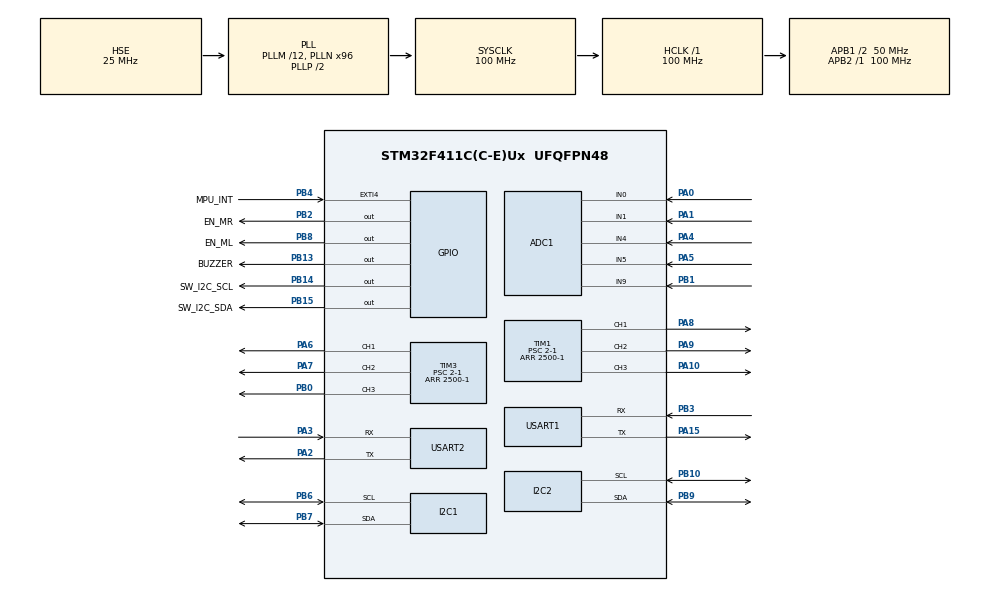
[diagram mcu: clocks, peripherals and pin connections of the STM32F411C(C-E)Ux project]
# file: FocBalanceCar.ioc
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ADC1.Channel-8\#ChannelRegularConversion=ADC_CHANNEL_1
ADC1.NbrOfConversionFlag=1
ADC1.Rank-8\#ChannelRegularConversion=1
ADC1.SamplingTime-8\#ChannelRegularConversion=ADC_SAMPLETIME_3CYCLES
ADC1.master=1
Dma.Request0=USART1_TX
Dma.Request1=USART2_TX
Dma.USART1_TX.0.Direction=DMA_MEMORY_TO_PERIPH
Dma.USART1_TX.0.FIFOMode=DMA_FIFOMODE_DISABLE
Dma.USART1_TX.0.Instance=DMA2_Stream7
Dma.USART1_TX.0.MemDataAlignment=DMA_MDATAALIGN_BYTE
Dma.USART1_TX.0.MemInc=DMA_MINC_ENABLE
Dma.USART1_TX.0.Mode=DMA_NORMAL
Dma.USART1_TX.0.PeriphDataAlignment=DMA_PDATAALIGN_BYTE
Dma.USART1_TX.0.PeriphInc=DMA_PINC_DISABLE
Dma.USART1_TX.0.Priority=DMA_PRIORITY_HIGH
Dma.USART2_TX.1.Direction=DMA_MEMORY_TO_PERIPH
Dma.USART2_TX.1.FIFOMode=DMA_FIFOMODE_DISABLE
Dma.USART2_TX.1.Instance=DMA1_Stream6
Dma.USART2_TX.1.MemDataAlignment=DMA_MDATAALIGN_BYTE
Dma.USART2_TX.1.MemInc=DMA_MINC_ENABLE
Dma.USART2_TX.1.Mode=DMA_NORMAL
Dma.USART2_TX.1.PeriphDataAlignment=DMA_PDATAALIGN_BYTE
Dma.USART2_TX.1.PeriphInc=DMA_PINC_DISABLE
Dma.USART2_TX.1.Priority=DMA_PRIORITY_HIGH
I2C1.I2C_Mode=I2C_Fast
I2C2.I2C_Mode=I2C_Fast
Mcu.Family=STM32F4
Mcu.Name=STM32F411C(C-E)Ux
Mcu.Package=UFQFPN48
NVIC.DMA1_Stream6_IRQn=true\:0\:0\:false\:false\:true\:false\:true\:true
NVIC.DMA2_Stream7_IRQn=true\:0\:0\:false\:false\:true\:false\:true\:true
NVIC.PriorityGroup=NVIC_PRIORITYGROUP_4
NVIC.TIM1_TRG_COM_TIM11_IRQn=true\:1\:0\:true\:false\:true\:true\:true\:true
NVIC.TIM1_UP_TIM10_IRQn=true\:1\:0\:true\:false\:true\:true\:true\:true
NVIC.USART1_IRQn=true\:0\:0\:true\:false\:true\:true\:true\:true
NVIC.USART2_IRQn=true\:0\:0\:true\:false\:true\:true\:true\:true
PA0-WKUP.Signal=ADCx_IN0
PA1.Signal=ADCx_IN1
PA10.GPIO_Speed=GPIO_SPEED_FREQ_HIGH
PA10.Signal=S_TIM1_CH3
PA13.Mode=Serial_Wire
PA13.Signal=SYS_JTMS-SWDIO
PA14.Mode=Serial_Wire
PA14.Signal=SYS_JTCK-SWCLK
PA15.Mode=Asynchronous
PA15.Signal=USART1_TX
PA2.Mode=Asynchronous
PA2.Signal=USART2_TX
PA3.Mode=Asynchronous
PA3.Signal=USART2_RX
PA4.Signal=ADCx_IN4
PA5.Signal=ADCx_IN5
PA6.GPIO_Speed=GPIO_SPEED_FREQ_HIGH
PA6.Signal=S_TIM3_CH1
PA7.GPIO_Speed=GPIO_SPEED_FREQ_HIGH
PA7.Signal=S_TIM3_CH2
PA8.GPIO_Speed=GPIO_SPEED_FREQ_HIGH
PA8.Signal=S_TIM1_CH1
PA9.GPIO_Speed=GPIO_SPEED_FREQ_HIGH
PA9.Signal=S_TIM1_CH2
PB0.Signal=S_TIM3_CH3
PB1.Signal=ADCx_IN9
PB10.Mode=I2C
PB10.Signal=I2C2_SCL
PB13.GPIO_Label=BUZZER
PB13.GPIO_Speed=GPIO_SPEED_FREQ_HIGH
PB13.Signal=GPIO_Output
PB14.GPIO_Label=SW_I2C_SCL
PB14.GPIO_ModeDefaultOutputPP=GPIO_MODE_OUTPUT_OD
PB14.GPIO_PuPd=GPIO_NOPULL
PB14.GPIO_Speed=GPIO_SPEED_FREQ_HIGH
PB14.Signal=GPIO_Output
PB15.GPIO_Label=SW_I2C_SDA
PB15.GPIO_ModeDefaultOutputPP=GPIO_MODE_OUTPUT_OD
PB15.GPIO_PuPd=GPIO_NOPULL
PB15.GPIO_Speed=GPIO_SPEED_FREQ_HIGH
PB15.Signal=GPIO_Output
PB2.GPIO_Label=EN_MR
PB2.GPIO_Speed=GPIO_SPEED_FREQ_HIGH
PB2.Signal=GPIO_Output
PB3.Mode=Asynchronous
PB3.Signal=USART1_RX
PB4.GPIO_Label=MPU_INT
PB4.GPIO_ModeDefaultEXTI=GPIO_MODE_IT_RISING_FALLING
PB4.Signal=GPXTI4
PB6.Mode=I2C
PB6.Signal=I2C1_SCL
PB7.Mode=I2C
PB7.Signal=I2C1_SDA
PB8.GPIO_Label=EN_ML
PB8.GPIO_Speed=GPIO_SPEED_FREQ_HIGH
PB8.Signal=GPIO_Output
PB9.Mode=I2C
PB9.Signal=I2C2_SDA
PH0\ -\ OSC_IN.Mode=HSE-External-Oscillator
PH0\ -\ OSC_IN.Signal=RCC_OSC_IN
PH1\ -\ OSC_OUT.Mode=HSE-External-Oscillator
PH1\ -\ OSC_OUT.Signal=RCC_OSC_OUT
ProjectManager.HeapSize=0x400
ProjectManager.StackSize=0x800
ProjectManager.TargetToolchain=MDK-ARM V5.32
RCC.48MHZClocksFreq_Value=50000000
RCC.AHBFreq_Value=100000000
RCC.APB1CLKDivider=RCC_HCLK_DIV2
RCC.APB1Freq_Value=50000000
RCC.APB1TimFreq_Value=100000000
RCC.APB2Freq_Value=100000000
RCC.APB2TimFreq_Value=100000000
RCC.CortexFreq_Value=100000000
RCC.HCLKFreq_Value=100000000
RCC.HSE_VALUE=25000000
RCC.HSI_VALUE=16000000
RCC.LSE_VALUE=32768
RCC.PLLM=12
RCC.PLLN=96
RCC.PLLSourceVirtual=RCC_PLLSOURCE_HSE
RCC.SYSCLKFreq_VALUE=100000000
RCC.SYSCLKSource=RCC_SYSCLKSOURCE_PLLCLK
RCC.VCOOutputFreq_Value=200000000
SH.ADCx_IN0.0=ADC1_IN0,IN0
SH.ADCx_IN1.0=ADC1_IN1,IN1
SH.ADCx_IN4.0=ADC1_IN4,IN4
SH.ADCx_IN5.0=ADC1_IN5,IN5
SH.ADCx_IN9.0=ADC1_IN9,IN9
SH.S_TIM1_CH1.0=TIM1_CH1,PWM Generation1 CH1
SH.S_TIM1_CH2.0=TIM1_CH2,PWM Generation2 CH2
SH.S_TIM1_CH3.0=TIM1_CH3,PWM Generation3 CH3
SH.S_TIM3_CH1.0=TIM3_CH1,PWM Generation1 CH1
SH.S_TIM3_CH2.0=TIM3_CH2,PWM Generation2 CH2
SH.S_TIM3_CH3.0=TIM3_CH3,PWM Generation3 CH3
STMicroelectronics.X-CUBE-ALGOBUILD.1.3.0.LibraryCcDSPOoLibraryJjDSPOoLibrary=true
TIM1.Channel-PWM\ Generation1\ CH1=TIM_CHANNEL_1
TIM1.Channel-PWM\ Generation2\ CH2=TIM_CHANNEL_2
TIM1.Channel-PWM\ Generation3\ CH3=TIM_CHANNEL_3
TIM1.Period=2500-1
TIM1.Prescaler=2-1
TIM10.Period=2000-1
TIM10.Prescaler=100-1
TIM11.Period=5000-1
TIM11.Prescaler=100-1
TIM3.Channel-PWM\ Generation1\ CH1=TIM_CHANNEL_1
TIM3.Channel-PWM\ Generation2\ CH2=TIM_CHANNEL_2
TIM3.Channel-PWM\ Generation3\ CH3=TIM_CHANNEL_3
TIM3.Period=2500-1
TIM3.Prescaler=2-1
USART1.VirtualMode=VM_ASYNC
USART2.VirtualMode=VM_ASYNC
VP_STMicroelectronics.X-CUBE-ALGOBUILD_VS_DSPOoLibraryJjLibrary_1.3.0_1.3.0.Mode=DSPOoLibraryJjLibrary
VP_TIM10_VS_ClockSourceINT.Mode=Enable_Timer
VP_TIM11_VS_ClockSourceINT.Mode=Enable_Timer
board=custom

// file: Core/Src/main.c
/* USER CODE BEGIN Header */
/**
  ******************************************************************************
  * @file           : main.c
  * @brief          : Main program body
  ******************************************************************************
  * @attention
  *
  * Copyright (c) 2024 STMicroelectronics.
  * All rights reserved.
  *
  * This software is licensed under terms that can be found in the LICENSE file
  * in the root directory of this software component.
  * If no LICENSE file comes with this software, it is provided AS-IS.
  *
  ******************************************************************************
  */
/* USER CODE END Header */
#include "main.h"
#include "adc.h"
#include "dma.h"
#include "i2c.h"
#include "tim.h"
#include "usart.h"
#include "gpio.h"

/* USER CODE BEGIN Includes */
#include "balance_car.h"
/* USER CODE END Includes */

void SystemClock_Config(void);

int main(void)
{

  /* MCU Configuration--------------------------------------------------------*/

  /* Reset of all peripherals, Initializes the Flash interface and the Systick. */
  HAL_Init();

  /* Configure the system clock */
  SystemClock_Config();

  /* Initialize all configured peripherals */
  MX_GPIO_Init();
  MX_DMA_Init();
  MX_TIM1_Init();
  MX_TIM3_Init();
  MX_TIM10_Init();
  MX_I2C1_Init();
  MX_I2C2_Init();
  MX_USART1_UART_Init();
  MX_USART2_UART_Init();
  MX_TIM11_Init();
  MX_ADC1_Init();
  /* USER CODE BEGIN 2 */
	balance_car_init();
  /* USER CODE END 2 */

  /* Infinite loop */
  /* USER CODE BEGIN WHILE */
  while (1)
  {
		balance_car_run();
    /* USER CODE END WHILE */

  }
}

void SystemClock_Config(void)
{
  RCC_OscInitTypeDef RCC_OscInitStruct = {0};
  RCC_ClkInitTypeDef RCC_ClkInitStruct = {0};

  /** Configure the main internal regulator output voltage
  */
  __HAL_RCC_PWR_CLK_ENABLE();
  __HAL_PWR_VOLTAGESCALING_CONFIG(PWR_REGULATOR_VOLTAGE_SCALE1);

  /** Initializes the RCC Oscillators according to the specified parameters
  * in the RCC_OscInitTypeDef structure.
  */
  RCC_OscInitStruct.OscillatorType = RCC_OSCILLATORTYPE_HSE;
  RCC_OscInitStruct.HSEState = RCC_HSE_ON;
  RCC_OscInitStruct.PLL.PLLState = RCC_PLL_ON;
  RCC_OscInitStruct.PLL.PLLSource = RCC_PLLSOURCE_HSE;
  RCC_OscInitStruct.PLL.PLLM = 12;
  RCC_OscInitStruct.PLL.PLLN = 96;
  RCC_OscInitStruct.PLL.PLLP = RCC_PLLP_DIV2;
  RCC_OscInitStruct.PLL.PLLQ = 4;
  if (HAL_RCC_OscConfig(&RCC_OscInitStruct) != HAL_OK)
  {
    Error_Handler();
  }

  /** Initializes the CPU, AHB and APB buses clocks
  */
  RCC_ClkInitStruct.ClockType = RCC_CLOCKTYPE_HCLK|RCC_CLOCKTYPE_SYSCLK
                              |RCC_CLOCKTYPE_PCLK1|RCC_CLOCKTYPE_PCLK2;
  RCC_ClkInitStruct.SYSCLKSource = RCC_SYSCLKSOURCE_PLLCLK;
  RCC_ClkInitStruct.AHBCLKDivider = RCC_SYSCLK_DIV1;
  RCC_ClkInitStruct.APB1CLKDivider = RCC_HCLK_DIV2;
  RCC_ClkInitStruct.APB2CLKDivider = RCC_HCLK_DIV1;

  if (HAL_RCC_ClockConfig(&RCC_ClkInitStruct, FLASH_LATENCY_3) != HAL_OK)
  {
    Error_Handler();
  }
}

void Error_Handler(void)
{
  __disable_irq();
  while (1)
  {
  }
}
